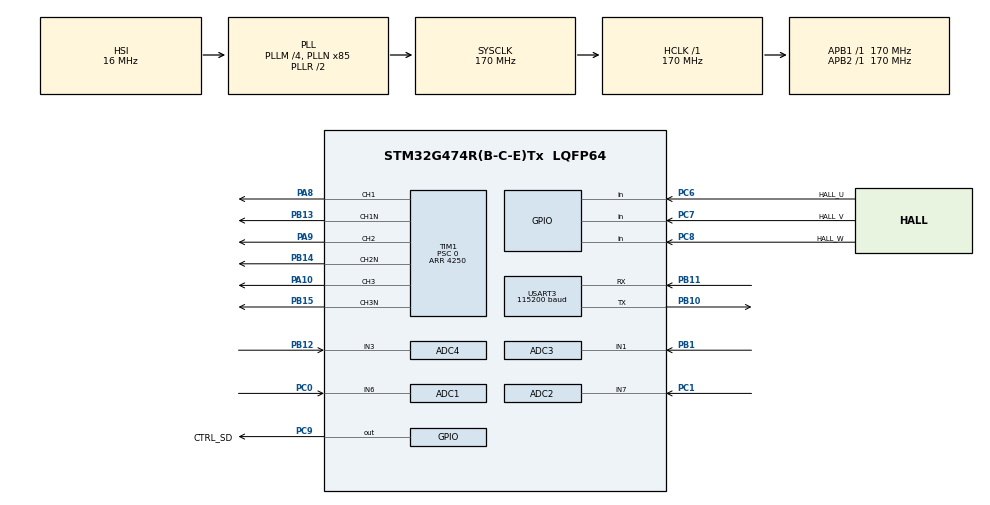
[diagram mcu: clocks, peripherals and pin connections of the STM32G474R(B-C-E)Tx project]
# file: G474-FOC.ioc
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ADC1.Channel-0\#ChannelRegularConversion=ADC_CHANNEL_6
ADC1.ClockPrescaler=ADC_CLOCK_ASYNC_DIV1
ADC1.ContinuousConvMode=DISABLE
ADC1.EOCSelection=ADC_EOC_SINGLE_CONV
ADC1.EnableInjectedConversion=ENABLE
ADC1.ExternalTrigConv=ADC_SOFTWARE_START
ADC1.ExternalTrigConvEdge=ADC_EXTERNALTRIGCONVEDGE_NONE
ADC1.ExternalTrigInjecConv=ADC_EXTERNALTRIGINJEC_T1_TRGO2
ADC1.ExternalTrigInjecConvEdge=ADC_EXTERNALTRIGINJECCONV_EDGE_RISING
ADC1.InjNumberOfConversion=1
ADC1.InjectedChannel-0\#ChannelInjectedConversion=ADC_CHANNEL_6
ADC1.InjectedConvMode=None
ADC1.InjectedOffsetNumber-0\#ChannelInjectedConversion=ADC_OFFSET_NONE
ADC1.InjectedRank-0\#ChannelInjectedConversion=1
ADC1.InjectedSamplingTime-0\#ChannelInjectedConversion=ADC_SAMPLETIME_12CYCLES_5
ADC1.NbrOfConversion=1
ADC1.NbrOfConversionFlag=1
ADC1.OffsetNumber-0\#ChannelRegularConversion=ADC_OFFSET_NONE
ADC1.Overrun=ADC_OVR_DATA_PRESERVED
ADC1.Rank-0\#ChannelRegularConversion=1
ADC1.SamplingTime-0\#ChannelRegularConversion=ADC_SAMPLETIME_12CYCLES_5
ADC1.ScanConvMode=ADC_SCAN_DISABLE
ADC1.master=1
ADC2.Channel-0\#ChannelRegularConversion=ADC_CHANNEL_7
ADC2.ClockPrescaler=ADC_CLOCK_ASYNC_DIV1
ADC2.ContinuousConvMode=DISABLE
ADC2.EOCSelection=ADC_EOC_SINGLE_CONV
ADC2.EnableInjectedConversion=ENABLE
ADC2.ExternalTrigConv=ADC_SOFTWARE_START
ADC2.ExternalTrigConvEdge=ADC_EXTERNALTRIGCONVEDGE_NONE
ADC2.ExternalTrigInjecConv=ADC_EXTERNALTRIGINJEC_T1_TRGO2
ADC2.ExternalTrigInjecConvEdge=ADC_EXTERNALTRIGINJECCONV_EDGE_RISING
ADC2.InjNumberOfConversion=1
ADC2.InjectedChannel-0\#ChannelInjectedConversion=ADC_CHANNEL_7
ADC2.InjectedConvMode=None
ADC2.InjectedOffsetNumber-0\#ChannelInjectedConversion=ADC_OFFSET_NONE
ADC2.InjectedRank-0\#ChannelInjectedConversion=1
ADC2.InjectedSamplingTime-0\#ChannelInjectedConversion=ADC_SAMPLETIME_12CYCLES_5
ADC2.NbrOfConversion=1
ADC2.NbrOfConversionFlag=1
ADC2.OffsetNumber-0\#ChannelRegularConversion=ADC_OFFSET_NONE
ADC2.Overrun=ADC_OVR_DATA_PRESERVED
ADC2.Rank-0\#ChannelRegularConversion=1
ADC2.SamplingTime-0\#ChannelRegularConversion=ADC_SAMPLETIME_12CYCLES_5
ADC2.ScanConvMode=ADC_SCAN_DISABLE
ADC2.master=1
ADC3.Channel-0\#ChannelRegularConversion=ADC_CHANNEL_1
ADC3.ClockPrescaler=ADC_CLOCK_ASYNC_DIV1
ADC3.ContinuousConvMode=DISABLE
ADC3.EOCSelection=ADC_EOC_SINGLE_CONV
ADC3.EnableInjectedConversion=ENABLE
ADC3.ExternalTrigConv=ADC_SOFTWARE_START
ADC3.ExternalTrigConvEdge=ADC_EXTERNALTRIGCONVEDGE_NONE
ADC3.ExternalTrigInjecConv=ADC_EXTERNALTRIGINJEC_T1_TRGO2
ADC3.ExternalTrigInjecConvEdge=ADC_EXTERNALTRIGINJECCONV_EDGE_RISING
ADC3.InjNumberOfConversion=1
ADC3.InjectedChannel-0\#ChannelInjectedConversion=ADC_CHANNEL_1
ADC3.InjectedConvMode=None
ADC3.InjectedOffsetNumber-0\#ChannelInjectedConversion=ADC_OFFSET_NONE
ADC3.InjectedRank-0\#ChannelInjectedConversion=1
ADC3.InjectedSamplingTime-0\#ChannelInjectedConversion=ADC_SAMPLETIME_24CYCLES_5
ADC3.NbrOfConversion=1
ADC3.NbrOfConversionFlag=1
ADC3.OffsetNumber-0\#ChannelRegularConversion=ADC_OFFSET_NONE
ADC3.Overrun=ADC_OVR_DATA_PRESERVED
ADC3.Rank-0\#ChannelRegularConversion=1
ADC3.SamplingTime-0\#ChannelRegularConversion=ADC_SAMPLETIME_24CYCLES_5
ADC3.ScanConvMode=ADC_SCAN_DISABLE
ADC3.master=1
ADC4.Channel-0\#ChannelRegularConversion=ADC_CHANNEL_3
ADC4.Channel-1\#ChannelRegularConversion=ADC_CHANNEL_VREFINT
ADC4.ClockPrescaler=ADC_CLOCK_ASYNC_DIV1
ADC4.ContinuousConvMode=DISABLE
ADC4.EOCSelection=ADC_EOC_SINGLE_CONV
ADC4.ExternalTrigConv=ADC_SOFTWARE_START
ADC4.ExternalTrigConvEdge=ADC_EXTERNALTRIGCONVEDGE_NONE
ADC4.LowPowerAutoWait=ENABLE
ADC4.NbrOfConversion=2
ADC4.NbrOfConversionFlag=1
ADC4.OffsetNumber-0\#ChannelRegularConversion=ADC_OFFSET_NONE
ADC4.OffsetNumber-1\#ChannelRegularConversion=ADC_OFFSET_NONE
ADC4.Overrun=ADC_OVR_DATA_PRESERVED
ADC4.Rank-0\#ChannelRegularConversion=1
ADC4.Rank-1\#ChannelRegularConversion=2
ADC4.SamplingTime-0\#ChannelRegularConversion=ADC_SAMPLETIME_247CYCLES_5
ADC4.SamplingTime-1\#ChannelRegularConversion=ADC_SAMPLETIME_247CYCLES_5
ADC4.ScanConvMode=ADC_SCAN_ENABLE
ADC4.master=1
Dma.Request0=USART3_TX
Dma.USART3_TX.0.Direction=DMA_MEMORY_TO_PERIPH
Dma.USART3_TX.0.EventEnable=DISABLE
Dma.USART3_TX.0.Instance=DMA1_Channel2
Dma.USART3_TX.0.MemDataAlignment=DMA_MDATAALIGN_BYTE
Dma.USART3_TX.0.MemInc=DMA_MINC_ENABLE
Dma.USART3_TX.0.Mode=DMA_NORMAL
Dma.USART3_TX.0.PeriphDataAlignment=DMA_PDATAALIGN_BYTE
Dma.USART3_TX.0.PeriphInc=DMA_PINC_DISABLE
Dma.USART3_TX.0.Polarity=HAL_DMAMUX_REQ_GEN_RISING
Dma.USART3_TX.0.Priority=DMA_PRIORITY_LOW
Dma.USART3_TX.0.RequestNumber=1
Dma.USART3_TX.0.SignalID=NONE
Dma.USART3_TX.0.SyncEnable=DISABLE
Dma.USART3_TX.0.SyncPolarity=HAL_DMAMUX_SYNC_NO_EVENT
Dma.USART3_TX.0.SyncRequestNumber=1
Dma.USART3_TX.0.SyncSignalID=NONE
Mcu.Family=STM32G4
Mcu.Name=STM32G474R(B-C-E)Tx
Mcu.Package=LQFP64
NVIC.ADC3_IRQn=true\:0\:0\:false\:false\:true\:false\:true\:true
NVIC.DMA1_Channel2_IRQn=true\:15\:0\:false\:false\:true\:false\:true\:true
NVIC.PriorityGroup=NVIC_PRIORITYGROUP_4
NVIC.TIM1_UP_TIM16_IRQn=true\:1\:0\:false\:false\:true\:false\:true\:true
NVIC.USART3_IRQn=true\:15\:0\:false\:false\:true\:false\:true\:true
PA10.Signal=S_TIM1_CH3
PA13.Mode=Serial_Wire
PA13.Signal=SYS_JTMS-SWDIO
PA14.Mode=Serial_Wire
PA14.Signal=SYS_JTCK-SWCLK
PA8.Signal=S_TIM1_CH1
PA9.Signal=S_TIM1_CH2
PB1.Mode=IN1-Single-Ended
PB1.Signal=ADC3_IN1
PB10.Mode=Asynchronous
PB10.Signal=USART3_TX
PB11.Mode=Asynchronous
PB11.Signal=USART3_RX
PB12.Mode=IN3-Single-Ended
PB12.Signal=ADC4_IN3
PB13.Mode=PWM Generation1 CH1 CH1N
PB13.Signal=TIM1_CH1N
PB14.Mode=PWM Generation2 CH2 CH2N
PB14.Signal=TIM1_CH2N
PB15.Mode=PWM Generation3 CH3 CH3N
PB15.Signal=TIM1_CH3N
PC0.Mode=IN6-Single-Ended
PC0.Signal=ADC1_IN6
PC1.Mode=IN7-Single-Ended
PC1.Signal=ADC2_IN7
PC6.GPIO_Label=HALL_U
PC6.GPIO_PuPd=GPIO_PULLUP
PC6.Signal=GPIO_Input
PC7.GPIO_Label=HALL_V
PC7.GPIO_PuPd=GPIO_PULLUP
PC7.Signal=GPIO_Input
PC8.GPIO_Label=HALL_W
PC8.GPIO_PuPd=GPIO_PULLUP
PC8.Signal=GPIO_Input
PC9.GPIO_Label=CTRL_SD
PC9.GPIO_PuPd=GPIO_PULLDOWN
PC9.Signal=GPIO_Output
ProjectManager.HeapSize=0x400
ProjectManager.StackSize=0x800
ProjectManager.TargetToolchain=MDK-ARM V5
RCC.ADC12CLockSelection=RCC_ADC12CLKSOURCE_PLL
RCC.ADC12Freq_Value=42500000
RCC.ADC345CLockSelection=RCC_ADC345CLKSOURCE_PLL
RCC.ADC345Freq_Value=42500000
RCC.AHBFreq_Value=170000000
RCC.APB1Freq_Value=170000000
RCC.APB1TimFreq_Value=170000000
RCC.APB2Freq_Value=170000000
RCC.APB2TimFreq_Value=170000000
RCC.CortexFreq_Value=170000000
RCC.EXTERNAL_CLOCK_VALUE=12288000
RCC.HCLKFreq_Value=170000000
RCC.HSE_VALUE=8000000
RCC.HSI48_VALUE=48000000
RCC.HSI_VALUE=16000000
RCC.LSE_VALUE=32768
RCC.PLLM=RCC_PLLM_DIV4
RCC.PLLN=85
RCC.PLLP=RCC_PLLP_DIV8
RCC.SYSCLKFreq_VALUE=170000000
RCC.SYSCLKSource=RCC_SYSCLKSOURCE_PLLCLK
RCC.USBFreq_Value=170000000
RCC.VCOOutputFreq_Value=340000000
SH.S_TIM1_CH1.0=TIM1_CH1,PWM Generation1 CH1 CH1N
SH.S_TIM1_CH2.0=TIM1_CH2,PWM Generation2 CH2 CH2N
SH.S_TIM1_CH3.0=TIM1_CH3,PWM Generation3 CH3 CH3N
TIM1.AutoReloadPreload=TIM_AUTORELOAD_PRELOAD_ENABLE
TIM1.AutomaticOutput=TIM_AUTOMATICOUTPUT_DISABLE
TIM1.BreakState=TIM_BREAK_DISABLE
TIM1.Channel-PWM\ Generation1\ CH1\ CH1N=TIM_CHANNEL_1
TIM1.Channel-PWM\ Generation2\ CH2\ CH2N=TIM_CHANNEL_2
TIM1.Channel-PWM\ Generation3\ CH3\ CH3N=TIM_CHANNEL_3
TIM1.Channel-PWM\ Generation4\ No\ Output=TIM_CHANNEL_4
TIM1.ClearInputSource=TIM_CLEARINPUTSOURCE_NONE
TIM1.ClockDivision=TIM_CLOCKDIVISION_DIV1
TIM1.CounterMode=TIM_COUNTERMODE_CENTERALIGNED1
TIM1.DeadTime=149
TIM1.Dithering=Disable
TIM1.OC4Preload_PWM=ENABLE
TIM1.OCIdleState_1=TIM_OCIDLESTATE_RESET
TIM1.OCMode_PWM-PWM\ Generation4\ No\ Output=TIM_OCMODE_PWM2
TIM1.OCNIdleState_1=TIM_OCNIDLESTATE_RESET
TIM1.OCNPolarity_1=TIM_OCNPOLARITY_HIGH
TIM1.OCPolarity_1=TIM_OCPOLARITY_HIGH
TIM1.OffStateIDLEMode=TIM_OSSI_ENABLE
TIM1.OffStateRunMode=TIM_OSSR_ENABLE
TIM1.PeriodNoDither=4250
TIM1.Prescaler=0
TIM1.PulseNoDither_1=0
TIM1.PulseNoDither_4=4165
TIM1.RepetitionCounter=1
TIM1.TIM_MasterOutputTrigger=TIM_TRGO_UPDATE
TIM1.TIM_MasterOutputTrigger2=TIM_TRGO2_OC4REF
TIM1.TIM_MasterSlaveMode=TIM_MASTERSLAVEMODE_DISABLE
USART3.BaudRate=115200
USART3.VirtualMode=VM_ASYNC
USART3.VirtualMode-Asynchronous=VM_ASYNC
VP_ADC4_Vref_Input.Mode=IN-Vrefint
VP_TIM1_VS_ClockSourceINT.Mode=Internal
VP_TIM1_VS_no_output4.Mode=PWM Generation4 No Output
board=custom

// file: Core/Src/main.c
/* USER CODE BEGIN Header */
/**
  ******************************************************************************
  * @file           : main.c
  * @brief          : Main program body
  ******************************************************************************
  * @attention
  *
  * Copyright (c) 2026 STMicroelectronics.
  * All rights reserved.
  *
  * This software is licensed under terms that can be found in the LICENSE file
  * in the root directory of this software component.
  * If no LICENSE file comes with this software, it is provided AS-IS.
  *
  ******************************************************************************
  */
/* USER CODE END Header */
#include "main.h"
#include "adc.h"
#include "dma.h"
#include "tim.h"
#include "usart.h"
#include "gpio.h"

/* USER CODE BEGIN Includes */
#include "app.h"
#include "pwm.h"

/* USER CODE END Includes */

void SystemClock_Config(void);

int main(void)
{

  /* MCU Configuration--------------------------------------------------------*/

  /* Reset of all peripherals, Initializes the Flash interface and the Systick. */
  HAL_Init();

  /* Configure the system clock */
  SystemClock_Config();

  /* Initialize all configured peripherals */
  MX_GPIO_Init();
  MX_DMA_Init();
  MX_ADC1_Init();
  MX_ADC2_Init();
  MX_ADC3_Init();
  MX_ADC4_Init();
  MX_TIM1_Init();
  MX_USART3_UART_Init();
  /* USER CODE BEGIN 2 */
  app_init();

  /* USER CODE END 2 */

  /* Infinite loop */
  while (1)
  {

    /* USER CODE BEGIN 3 */
    app_task();
  }
  /* USER CODE END 3 */
}

void SystemClock_Config(void)
{
  RCC_OscInitTypeDef RCC_OscInitStruct = {0};
  RCC_ClkInitTypeDef RCC_ClkInitStruct = {0};

  /** Configure the main internal regulator output voltage
  */
  HAL_PWREx_ControlVoltageScaling(PWR_REGULATOR_VOLTAGE_SCALE1_BOOST);

  /** Initializes the RCC Oscillators according to the specified parameters
  * in the RCC_OscInitTypeDef structure.
  */
  RCC_OscInitStruct.OscillatorType = RCC_OSCILLATORTYPE_HSI;
  RCC_OscInitStruct.HSIState = RCC_HSI_ON;
  RCC_OscInitStruct.HSICalibrationValue = RCC_HSICALIBRATION_DEFAULT;
  RCC_OscInitStruct.PLL.PLLState = RCC_PLL_ON;
  RCC_OscInitStruct.PLL.PLLSource = RCC_PLLSOURCE_HSI;
  RCC_OscInitStruct.PLL.PLLM = RCC_PLLM_DIV4;
  RCC_OscInitStruct.PLL.PLLN = 85;
  RCC_OscInitStruct.PLL.PLLP = RCC_PLLP_DIV8;
  RCC_OscInitStruct.PLL.PLLQ = RCC_PLLQ_DIV2;
  RCC_OscInitStruct.PLL.PLLR = RCC_PLLR_DIV2;
  if (HAL_RCC_OscConfig(&RCC_OscInitStruct) != HAL_OK)
  {
    Error_Handler();
  }

  /** Initializes the CPU, AHB and APB buses clocks
  */
  RCC_ClkInitStruct.ClockType = RCC_CLOCKTYPE_HCLK|RCC_CLOCKTYPE_SYSCLK
                              |RCC_CLOCKTYPE_PCLK1|RCC_CLOCKTYPE_PCLK2;
  RCC_ClkInitStruct.SYSCLKSource = RCC_SYSCLKSOURCE_PLLCLK;
  RCC_ClkInitStruct.AHBCLKDivider = RCC_SYSCLK_DIV1;
  RCC_ClkInitStruct.APB1CLKDivider = RCC_HCLK_DIV1;
  RCC_ClkInitStruct.APB2CLKDivider = RCC_HCLK_DIV1;

  if (HAL_RCC_ClockConfig(&RCC_ClkInitStruct, FLASH_LATENCY_4) != HAL_OK)
  {
    Error_Handler();
  }
}

void Error_Handler(void)
{
  /* USER CODE BEGIN Error_Handler_Debug */
  bsp_pwm_stop_emergency();
  /* User can add his own implementation to report the HAL error return state */
  __disable_irq();
  while (1)
  {
  }
  /* USER CODE END Error_Handler_Debug */
}
